# AT91SAM9X35 register map
Vendor: Atmel; Series: SAM9X; File version: 20130207
Registers are 32-bit, read-write, reset 0x0 unless marked. A register's access mark holds for its fields unless they carry their own. Offsets are from the block's base; [hi:lo] are bit positions; {n}, {i} and the like mark numbered series.

## ADC — Analog-to-Digital Converter
Base 0xF804C000; register names take the prefix ADC_
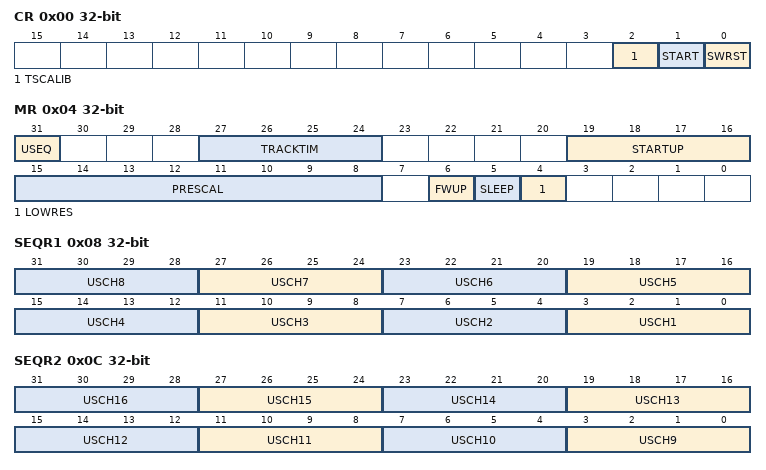
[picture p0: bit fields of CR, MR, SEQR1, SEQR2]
0x00 CR wo reset not defined — Control Register
  [2] TSCALIB — Touchscreen Calibration
  [1] START — Start Conversion
  [0] SWRST — Software Reset
0x04 MR — Mode Register
  [31] USEQ — Use Sequence Enable
    0=NUM_ORDER (Normal Mode: The controller converts channels in a simple numeric order depending only on the channel index.); 1=REG_ORDER (User Sequence Mode: The sequence respects what is defined in ADC_SEQR1 and ADC_SEQR2 registers and can be used to convert several times the same channel.)
  [27:24] TRACKTIM — Tracking Time
  [19:16] STARTUP — Start Up Time
    0=SUT0 (0 periods of ADCClock); 1=SUT8 (8 periods of ADCClock); 2=SUT16 (16 periods of ADCClock); 3=SUT24 (24 periods of ADCClock); 4=SUT64 (64 periods of ADCClock); 5=SUT80 (80 periods of ADCClock); 6=SUT96 (96 periods of ADCClock); 7=SUT112 (112 periods of ADCClock); 8=SUT512 (512 periods of ADCClock); 9=SUT576 (576 periods of ADCClock); 10=SUT640 (640 periods of ADCClock); 11=SUT704 (704 periods of ADCClock); 12=SUT768 (768 periods of ADCClock); 13=SUT832 (832 periods of ADCClock); 14=SUT896 (896 periods of ADCClock); 15=SUT960 (960 periods of ADCClock)
  [15:8] PRESCAL — Prescaler Rate Selection
  [6] FWUP — Fast Wake Up
    0=OFF (Normal Sleep Mode: The sleep mode is defined by the SLEEP bit); 1=ON (Fast Wake Up Sleep Mode: The Voltage reference is ON between conversions and ADC Core is OFF)
  [5] SLEEP — Sleep Mode
    0=NORMAL (Normal Mode: The ADC Core and reference voltage circuitry are kept ON between conversions); 1=SLEEP (Sleep Mode: The ADC Core and reference voltage circuitry are OFF between conversions)
  [4] LOWRES — Resolution
    0=BITS_10 (10-bit resolution); 1=BITS_8 (8-bit resolution)
0x08 SEQR1 — Channel Sequence Register 1
  [4n-1:4n-4] USCH{n} (n=1..8) — User Sequence Number {n}
0x0C SEQR2 — Channel Sequence Register 2
  [4n-33:4n-36] USCH{n} (n=9..16) — User Sequence Number {n}
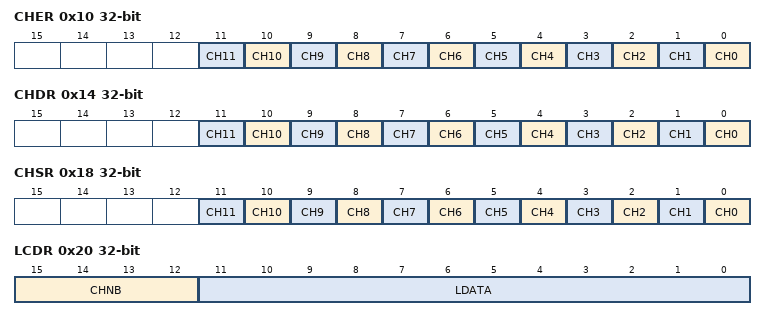
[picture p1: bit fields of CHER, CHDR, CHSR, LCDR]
0x10 CHER wo reset not defined — Channel Enable Register
  [n] CH{n} (n=0..11) — Channel {n} Enable
0x14 CHDR wo reset not defined — Channel Disable Register
  [n] CH{n} (n=0..11) — Channel {n} Disable
0x18 CHSR ro — Channel Status Register
  [n] CH{n} (n=0..11) — Channel {n} Status
0x20 LCDR ro — Last Converted Data Register
  [15:12] CHNB — Channel Number
  [11:0] LDATA — Last Data Converted
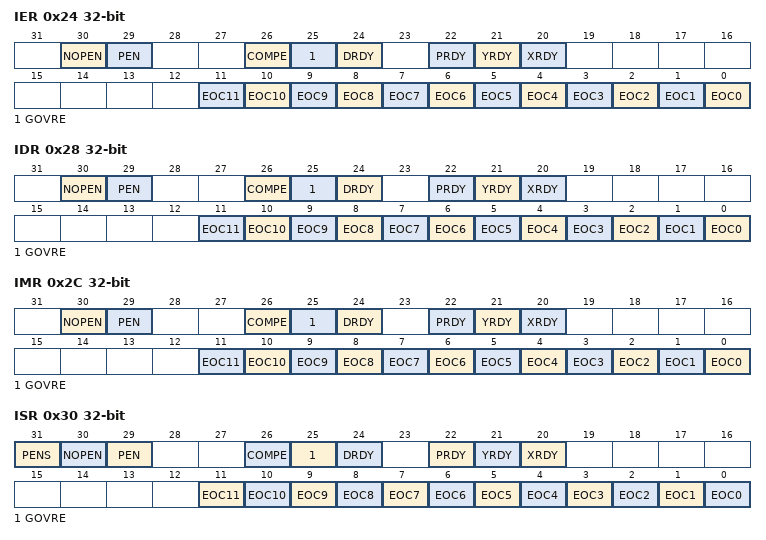
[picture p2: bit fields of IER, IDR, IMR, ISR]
0x24 IER wo reset not defined — Interrupt Enable Register
  [30] NOPEN — No Pen Contact Interrupt Enable
  [29] PEN — Pen Contact Interrupt Enable
  [26] COMPE — Comparison Event Interrupt Enable
  [25] GOVRE — General Overrun Error Interrupt Enable
  [24] DRDY — Data Ready Interrupt Enable
  [22] PRDY — Touchscreen Measure Pressure Ready Interrupt Enable
  [21] YRDY — Touchscreen Measure YPOS Ready Interrupt Enable
  [20] XRDY — Touchscreen Measure XPOS Ready Interrupt Enable
  [n] EOC{n} (n=0..11) — End of Conversion Interrupt Enable {n}
0x28 IDR wo reset not defined — Interrupt Disable Register
  [30] NOPEN — No Pen Contact Interrupt Disable
  [29] PEN — Pen Contact Interrupt Disable
  [26] COMPE — Comparison Event Interrupt Disable
  [25] GOVRE — General Overrun Error Interrupt Disable
  [24] DRDY — Data Ready Interrupt Disable
  [22] PRDY — Touchscreen Measure Pressure Ready Interrupt Disable
  [21] YRDY — Touchscreen Measure YPOS Ready Interrupt Disable
  [20] XRDY — Touchscreen Measure XPOS Ready Interrupt Disable
  [n] EOC{n} (n=0..11) — End of Conversion Interrupt Disable {n}
0x2C IMR ro — Interrupt Mask Register
  [30] NOPEN — No Pen Contact Interrupt Mask
  [29] PEN — Pen Contact Interrupt Mask
  [26] COMPE — Comparison Event Interrupt Mask
  [25] GOVRE — General Overrun Error Interrupt Mask
  [24] DRDY — Data Ready Interrupt Mask
  [22] PRDY — Touchscreen Measure Pressure Ready Interrupt Mask
  [21] YRDY — Touchscreen Measure YPOS Ready Interrupt Mask
  [20] XRDY — Touchscreen Measure XPOS Ready Interrupt Mask
  [n] EOC{n} (n=0..11) — End of Conversion Interrupt Mask {n}
0x30 ISR ro — Interrupt Status Register
  [31] PENS — Pen detect Status
  [30] NOPEN — No Pen contact
  [29] PEN — Pen contact
  [26] COMPE — Comparison Error
  [25] GOVRE — General Overrun Error
  [24] DRDY — Data Ready
  [22] PRDY — Touchscreen Pressure Measure Ready
  [21] YRDY — Touchscreen YPOS Measure Ready
  [20] XRDY — Touchscreen XPOS Measure Ready
  [n] EOC{n} (n=0..11) — End of Conversion {n}
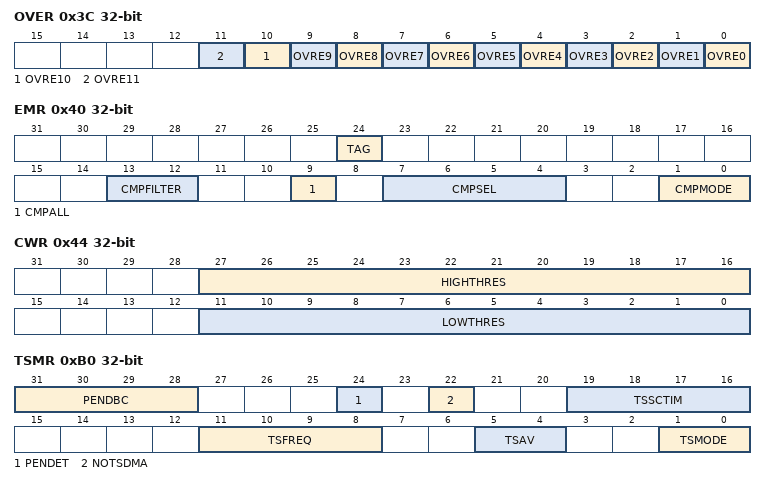
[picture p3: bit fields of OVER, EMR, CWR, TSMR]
0x3C OVER ro — Overrun Status Register
  [n] OVRE{n} (n=0..11) — Overrun Error {n}
0x40 EMR — Extended Mode Register
  [24] TAG — TAG of the ADC_LDCR register
  [13:12] CMPFILTER — Compare Event Filtering
  [9] CMPALL — Compare All Channels
  [7:4] CMPSEL — Comparison Selected Channel
  [1:0] CMPMODE — Comparison Mode
    0=LOW (Generates an event when the converted data is lower than the low threshold of the window.); 1=HIGH (Generates an event when the converted data is higher than the high threshold of the window.); 2=IN (Generates an event when the converted data is in the comparison window.); 3=OUT (Generates an event when the converted data is out of the comparison window.)
0x44 CWR — Compare Window Register
  [27:16] HIGHTHRES — High Threshold
  [11:0] LOWTHRES — Low Threshold
{0x50+4i} CDR[{i}] (i=0..11) ro reset not defined — Channel Data Register
  [11:0] DATA — Converted Data
0x94 ACR reset 0x100 — Analog Control Register
  [1:0] PENDETSENS — Pen Detection Sensitivity
0xB0 TSMR — Touchscreen Mode Register
  [31:28] PENDBC — Pen Detect Debouncing Period
  [24] PENDET — Pen Contact Detection Enable
  [22] NOTSDMA — No TouchScreen DMA
  [19:16] TSSCTIM — Touchscreen Switches Closure Time
  [11:8] TSFREQ — Touchscreen Frequency
  [5:4] TSAV — Touchscreen Average
    0=NO_FILTER (No Filtering. Only one ADC conversion per measure); 1=AVG2CONV (Averages 2 ADC conversions); 2=AVG4CONV (Averages 4 ADC conversions); 3=AVG8CONV (Averages 8 ADC conversions)
  [1:0] TSMODE — Touchscreen Mode
    0=NONE (No Touchscreen); 1=4_WIRE_NO_PM (4-wire Touchscreen without pressure measurement); 2=4_WIRE (4-wire Touchscreen with pressure measurement); 3=5_WIRE (5-wire Touchscreen)
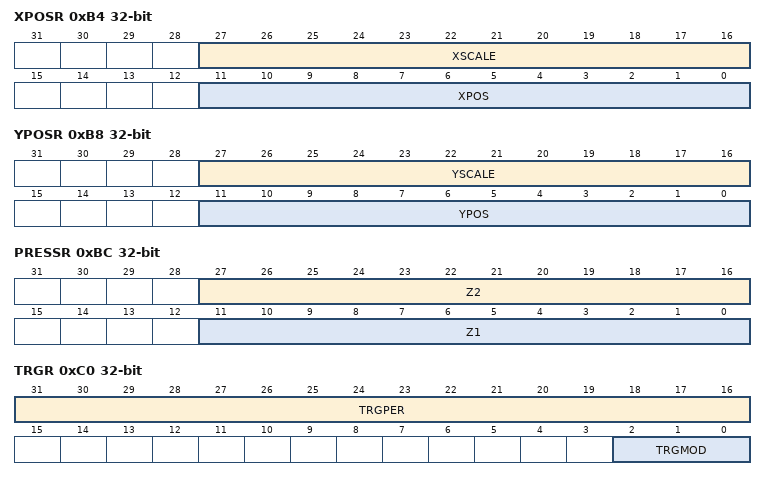
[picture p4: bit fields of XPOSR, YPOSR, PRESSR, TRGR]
0xB4 XPOSR ro — Touchscreen X Position Register
  [27:16] XSCALE — Scale of XPOS
  [11:0] XPOS — X Position
0xB8 YPOSR ro — Touchscreen Y Position Register
  [27:16] YSCALE — Scale of YPOS
  [11:0] YPOS — Y Position
0xBC PRESSR ro — Touchscreen Pressure Register
  [27:16] Z2 — Data of Z2 Measurement
  [11:0] Z1 — Data of Z1 Measurement
0xC0 TRGR — Trigger Register
  [31:16] TRGPER — Trigger Period
  [2:0] TRGMOD — Trigger Mode
    0=NO_TRIGGER (No trigger, only software trigger can start conversions); 1=EXT_TRIG_RISE (External Trigger Rising Edge); 2=EXT_TRIG_FALL (External Trigger Falling Edge); 3=EXT_TRIG_ANY (External Trigger Any Edge); 4=PEN_TRIG (Pen Detect Trigger (shall be selected only if PENDET is set and TSAMOD = Touchscreen only mode)); 5=PERIOD_TRIG (Periodic Trigger (TRGPER shall be initiated appropriately)); 6=CONTINUOUS (Continuous Mode)
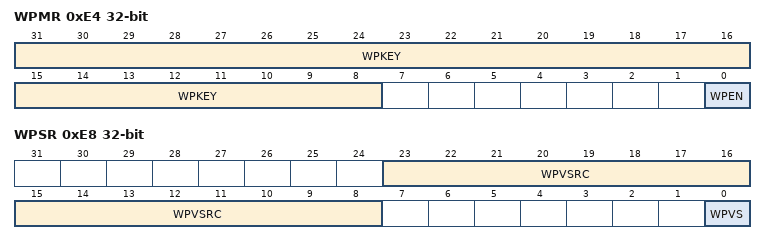
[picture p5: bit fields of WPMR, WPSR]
0xE4 WPMR — Write Protect Mode Register
  [31:8] WPKEY — Write Protect KEY
  [0] WPEN — Write Protect Enable
0xE8 WPSR ro — Write Protect Status Register
  [23:8] WPVSRC — Write Protect Violation Source
  [0] WPVS — Write Protect Violation Status
